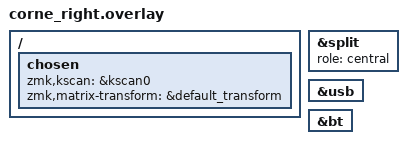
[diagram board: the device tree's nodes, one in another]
/ {
    chosen {
        zmk,kscan = &kscan0;
        zmk,matrix-transform = &default_transform;
    };
};

/* RIGHT side is the brain */
&split {
    role = "central";
};

/* Enable USB + BLE */
&usb {
    status = "okay";
};

&bt {
    status = "okay";
};
